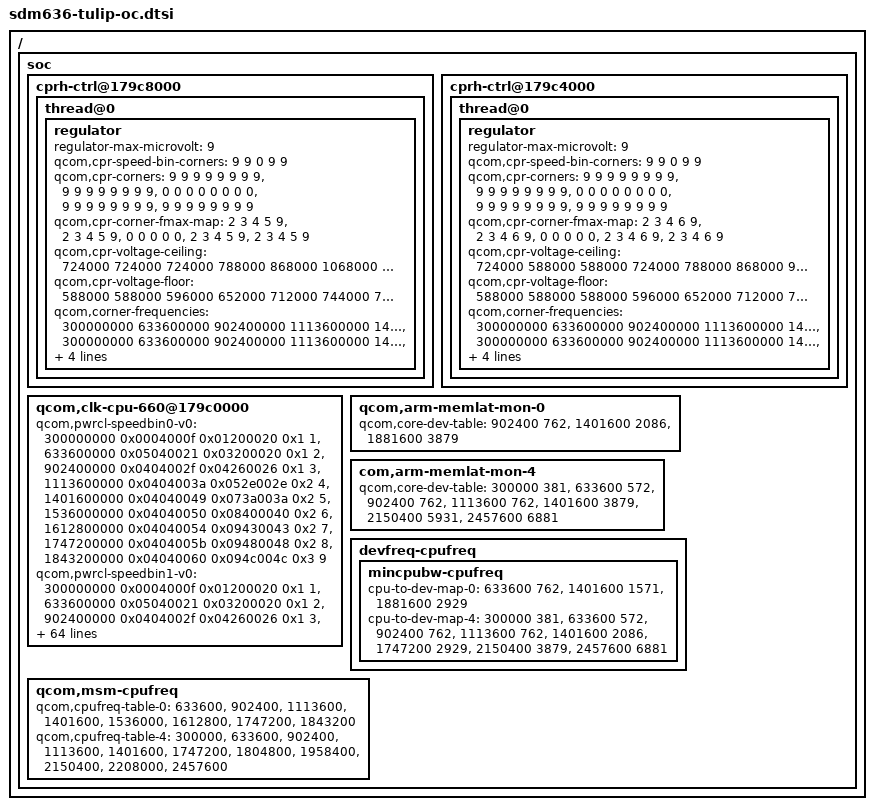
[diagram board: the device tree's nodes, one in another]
/*
 * Copyright (c) 2015-2017, The Linux Foundation. All rights reserved.
 *
 * This program is free software; you can redistribute it and/or modify
 * it under the terms of the GNU General Public License version 2 and
 * only version 2 as published by the Free Software Foundation.
 *
 * This program is distributed in the hope that it will be useful,
 * but WITHOUT ANY WARRANTY; without even the implied warranty of
 * MERCHANTABILITY or FITNESS FOR A PARTICULAR PURPOSE.  See the
 * GNU General Public License for more details.
 */

/ {
soc {
	cprh-ctrl@179c8000 {
		thread@0 {
			regulator {
				regulator-max-microvolt = <9>;
				qcom,cpr-speed-bin-corners = <9 9 0 9 9>;
				qcom,cpr-corners =
					/* Speed bin 0 */
					<9 9 9 9 9 9 9 9>,

					/* Speed bin 1 */
					<9 9 9 9 9 9 9 9>,

					/* Speed bin 2 */
					<0 0 0 0 0 0 0 0>,

					/* Speed bin 3 */
					<9 9 9 9 9 9 9 9>,

					/* Speed bin 4 */
					<9 9 9 9 9 9 9 9>;

				qcom,cpr-corner-fmax-map =
					/* Speed bin 0 */
					<2 3 4 5 9>,

					/* Speed bin 1 */
					<2 3 4 5 9>,

					/* Speed bin 2 */
					<0 0 0 0 0>,

					/* Speed bin 3 */
					<2 3 4 5 9>,

					/* Speed bin 4 */
					<2 3 4 5 9>;

				qcom,cpr-voltage-ceiling =
					< 724000  724000  724000  788000  868000
					 1068000 1068000 1068000 1068000>;

				qcom,cpr-voltage-floor =
					<588000  588000  596000  652000  712000
					 744000  784000  784000  844000>;

				qcom,corner-frequencies =
					/* Speed bin 0 */
					<300000000  633600000  902400000
					1113600000 1401600000 1536000000
					1612800000 1747200000 1843200000>,

					/* Speed bin 1 */
					<300000000  633600000  902400000
					1113600000 1401600000 1536000000
					1612800000 1747200000 1843200000>,

					/* Speed bin 3 */
					<300000000  633600000  902400000
					1113600000 1401600000 1536000000
					1612800000 1747200000 1843200000>,

					/* Speed bin 4 */
					<300000000  633600000  902400000
					1113600000 1401600000 1536000000
					1612800000 1747200000 1843200000>;

				qcom,cpr-floor-to-ceiling-max-range =
					<32000  32000  32000  40000  44000
					 40000  40000  40000  40000>;
			};
		};
	};

	cprh-ctrl@179c4000 {
		thread@0 {
			regulator {
				regulator-max-microvolt = <9>;
				qcom,cpr-speed-bin-corners = <9 9 0 9 9>;
				qcom,cpr-corners =
					/* Speed-bin 0 */
					<9 9 9 9 9 9 9 9>,

					/* Speed-bin 1 */
					<9 9 9 9 9 9 9 9>,

					/* Speed-bin 1 */
					<0 0 0 0 0 0 0 0>,

					/* Speed-bin 3 */
					<9 9 9 9 9 9 9 9>,

					/* Speed-bin 4 */
					<9 9 9 9 9 9 9 9>;

				qcom,cpr-corner-fmax-map =
					/* Speed-bin 0 */
					<2 3 4 6 9>,

					/* Speed-bin 1 */
					<2 3 4 6 9>,

					/* Speed-bin 2 */
					<0 0 0 0 0>,

					/* Speed-bin 3 */
					<2 3 4 6 9>,

					/* Speed-bin 4 */
					<2 3 4 6 9>;

				qcom,cpr-voltage-ceiling =
					<724000  588000  588000  724000  788000  868000
					 988000  988000 1068000>;

				qcom,cpr-voltage-floor =
					<588000  588000  588000  596000  652000  712000
					 744000  784000  844000>;

				qcom,corner-frequencies =
					/* Speed bin 0 */
					<300000000  633600000  902400000
                                         1113600000 1401600000 1747200000
                                         2150400000 2208000000 2457600000>,

					/* Speed bin 1 */
					<300000000  633600000  902400000
                                         1113600000 1401600000 1747200000
                                         2150400000 2208000000 2457600000>,

					/* Speed bin 3 */
					<300000000  633600000  902400000
                                         1113600000 1401600000 1747200000
                                         2150400000 2208000000 2457600000>,

					/* Speed bin 4 */
					<300000000  633600000  902400000
                                         1113600000 1401600000 1747200000
                                         2150400000 2208000000 2457600000>;

				qcom,cpr-floor-to-ceiling-max-range =
					<40000  40000  40000  40000  40000  40000
					 66000  66000  40000>;
			};
		};
	};
	qcom,clk-cpu-660@179c0000 {
		qcom,pwrcl-speedbin0-v0 =
			<   300000000 0x0004000f 0x01200020 0x1 1 >,
			<   633600000 0x05040021 0x03200020 0x1 2 >,
			<   902400000 0x0404002f 0x04260026 0x1 3 >,
			<  1113600000 0x0404003a 0x052e002e 0x2 4 >,
			<  1401600000 0x04040049 0x073a003a 0x2 5 >,
			<  1536000000 0x04040050 0x08400040 0x2 6 >,
 			<  1612800000 0x04040054 0x09430043 0x2 7 >,
			<  1747200000 0x0404005b 0x09480048 0x2 8 >,
			<  1843200000 0x04040060 0x094c004c 0x3 9 >;

		qcom,pwrcl-speedbin1-v0 =
			<   300000000 0x0004000f 0x01200020 0x1 1 >,
			<   633600000 0x05040021 0x03200020 0x1 2 >,
			<   902400000 0x0404002f 0x04260026 0x1 3 >,
			<  1113600000 0x0404003a 0x052e002e 0x2 4 >,
			<  1401600000 0x04040049 0x073a003a 0x2 5 >,
			<  1536000000 0x04040050 0x08400040 0x2 6 >,
 			<  1612800000 0x04040054 0x09430043 0x2 7 >,
			<  1747200000 0x0404005b 0x09480048 0x2 8 >,
			<  1843200000 0x04040060 0x094c004c 0x3 9 >;

		qcom,pwrcl-speedbin3-v0 =
			<   300000000 0x0004000f 0x01200020 0x1 1 >,
			<   633600000 0x05040021 0x03200020 0x1 2 >,
			<   902400000 0x0404002f 0x04260026 0x1 3 >,
			<  1113600000 0x0404003a 0x052e002e 0x2 4 >,
			<  1401600000 0x04040049 0x073a003a 0x2 5 >,
			<  1536000000 0x04040050 0x08400040 0x2 6 >,
 			<  1612800000 0x04040054 0x09430043 0x2 7 >,
			<  1747200000 0x0404005b 0x09480048 0x2 8 >,
			<  1843200000 0x04040060 0x094c004c 0x3 9 >;

		qcom,pwrcl-speedbin4-v0 =
			<   300000000 0x0004000f 0x01200020 0x1 1 >,
			<   633600000 0x05040021 0x03200020 0x1 2 >,
			<   902400000 0x0404002f 0x04260026 0x1 3 >,
			<  1113600000 0x0404003a 0x052e002e 0x2 4 >,
			<  1401600000 0x04040049 0x073a003a 0x2 5 >,
			<  1536000000 0x04040050 0x08400040 0x2 6 >,
 			<  1612800000 0x04040054 0x09430043 0x2 7 >,
			<  1747200000 0x0404005b 0x09480048 0x2 7 >,
			<  1843200000 0x04040060 0x094c004c 0x3 8 >;

		qcom,perfcl-speedbin0-v0 =
			<   300000000 0x0004000f 0x01200020 0x1 1 >,
                        <   633600000 0x05040021 0x03200020 0x1 2 >,
                        <   902400000 0x0404002f 0x04260026 0x1 3 >,
			<  1113600000 0x0404003a 0x052e002e 0x1 4 >,
			<  1401600000 0x04040049 0x073a003a 0x2 5 >,
			<  1747200000 0x0404005b 0x09480048 0x2 6 >,
			<  1958400000 0x04040066 0x0a510051 0x2 7 >,
			<  2150400000 0x04040070 0x0b590059 0x2 8 >,
			<  2457600000 0x04040080 0x0c660066 0x3 9 >;

		qcom,perfcl-speedbin1-v0 =
			<   300000000 0x0004000f 0x01200020 0x1 1 >,
                        <   633600000 0x05040021 0x03200020 0x1 2 >,
                        <   902400000 0x0404002f 0x04260026 0x1 3 >,
			<  1113600000 0x0404003a 0x052e002e 0x1 4 >,
			<  1401600000 0x04040049 0x073a003a 0x2 5 >,
			<  1747200000 0x0404005b 0x09480048 0x2 6 >,
			<  1958400000 0x04040066 0x0a510051 0x2 7 >,
			<  2150400000 0x04040070 0x0b590059 0x2 8 >,
			<  2208000000 0x04040073 0x0b5c005c 0x3 9 >;

		qcom,perfcl-speedbin3-v0 =
			<   300000000 0x0004000f 0x01200020 0x1 1 >,
                        <   633600000 0x05040021 0x03200020 0x1 2 >,
                        <   902400000 0x0404002f 0x04260026 0x1 3 >,
			<  1113600000 0x0404003a 0x052e002e 0x1 4 >,
			<  1401600000 0x04040049 0x073a003a 0x2 5 >,
			<  1747200000 0x0404005b 0x09480048 0x2 6 >,
			<  1958400000 0x04040066 0x0a510051 0x2 7 >,
			<  2150400000 0x04040070 0x0b590059 0x2 8 >,
			<  2457600000 0x04040080 0x0c660066 0x3 9 >;

		qcom,perfcl-speedbin4-v0 =
			<   300000000 0x0004000f 0x01200020 0x1 1 >,
                        <   633600000 0x05040021 0x03200020 0x1 2 >,
                        <   902400000 0x0404002f 0x04260026 0x1 3 >,
			<  1113600000 0x0404003a 0x052e002e 0x1 4 >,
			<  1401600000 0x04040049 0x073a003a 0x2 5 >,
			<  1747200000 0x0404005b 0x09480048 0x2 6 >,
			<  1958400000 0x04040066 0x0a510051 0x2 7 >;
	};

	qcom,arm-memlat-mon-0 {
		qcom,core-dev-table =
			< 902400 762 >,
			< 1401600 2086 >,
			< 1881600 3879 >;
	};
	com,arm-memlat-mon-4 {
		qcom,core-dev-table =
                        < 300000 381 >,
			< 633600 572 >,
			< 902400 762 >,
			< 1113600 762 >,
			< 1401600 3879 >,
			< 2150400 5931 >,
			< 2457600 6881 >;
	};
	devfreq-cpufreq {
		mincpubw-cpufreq {
			cpu-to-dev-map-0 =
				< 633600 762 >,
				< 1401600 1571 >,
				< 1881600 2929 >;

			cpu-to-dev-map-4 =
                                < 300000 381 >,
				< 633600 572 >,
				< 902400 762 >,
				< 1113600 762 >,
				< 1401600 2086 >,
				< 1747200 2929 >,
				< 2150400 3879 >,
				< 2457600 6881 >;
		};
	};
	qcom,msm-cpufreq {
		qcom,cpufreq-table-0 =
			<  633600 >,
			<  902400 >,
			< 1113600 >,
			< 1401600 >,
			< 1536000 >,
			< 1612800 >,
			< 1747200 >,
			< 1843200 >;

		qcom,cpufreq-table-4 =
			<  300000 >,
			<  633600 >,
			<  902400 >,
			< 1113600 >,
			< 1401600 >,
			< 1747200 >,
			< 1804800 >,
			< 1958400 >,
			< 2150400 >,
			< 2208000 >,
			< 2457600 >;
	};
};
};
